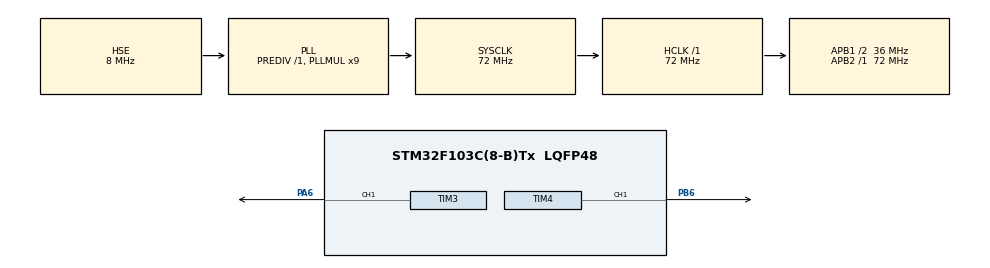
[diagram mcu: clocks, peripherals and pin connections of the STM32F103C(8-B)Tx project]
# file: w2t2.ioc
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Mcu.Family=STM32F1
Mcu.Name=STM32F103C(8-B)Tx
Mcu.Package=LQFP48
NVIC.PriorityGroup=NVIC_PRIORITYGROUP_4
NVIC.TIM2_IRQn=true\:0\:0\:false\:false\:true\:true\:true\:true
PA13.Mode=Serial_Wire
PA13.Signal=SYS_JTMS-SWDIO
PA14.Mode=Serial_Wire
PA14.Signal=SYS_JTCK-SWCLK
PA6.Signal=S_TIM3_CH1
PB6.Signal=S_TIM4_CH1
PD0-OSC_IN.Mode=HSE-External-Oscillator
PD0-OSC_IN.Signal=RCC_OSC_IN
PD1-OSC_OUT.Mode=HSE-External-Oscillator
PD1-OSC_OUT.Signal=RCC_OSC_OUT
ProjectManager.HeapSize=0x200
ProjectManager.StackSize=0x400
ProjectManager.TargetToolchain=MDK-ARM V5.32
RCC.AHBFreq_Value=72000000
RCC.APB1CLKDivider=RCC_HCLK_DIV2
RCC.APB1Freq_Value=36000000
RCC.APB1TimFreq_Value=72000000
RCC.APB2Freq_Value=72000000
RCC.APB2TimFreq_Value=72000000
RCC.HCLKFreq_Value=72000000
RCC.PLLMUL=RCC_PLL_MUL9
RCC.PLLSourceVirtual=RCC_PLLSOURCE_HSE
RCC.SYSCLKFreq_VALUE=72000000
RCC.SYSCLKSource=RCC_SYSCLKSOURCE_PLLCLK
RCC.USBFreq_Value=72000000
SH.S_TIM3_CH1.0=TIM3_CH1,PWM Generation1 CH1
SH.S_TIM4_CH1.0=TIM4_CH1,PWM Generation1 CH1
TIM2.Period=9999
TIM2.Prescaler=71
TIM3.Channel-PWM\ Generation1\ CH1=TIM_CHANNEL_1
TIM3.Period=999
TIM3.Prescaler=71
TIM4.Channel-PWM\ Generation1\ CH1=TIM_CHANNEL_1
TIM4.Period=19999
TIM4.Prescaler=71
VP_TIM2_VS_ClockSourceINT.Mode=Internal
VP_TIM3_VS_ClockSourceINT.Mode=Internal
VP_TIM4_VS_ClockSourceINT.Mode=Internal
board=custom

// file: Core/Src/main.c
/* USER CODE BEGIN Header */
/**
  ******************************************************************************
  * @file           : main.c
  * @brief          : Main program body
  ******************************************************************************
  * @attention
  *
  * Copyright (c) 2026 STMicroelectronics.
  * All rights reserved.
  *
  * This software is licensed under terms that can be found in the LICENSE file
  * in the root directory of this software component.
  * If no LICENSE file comes with this software, it is provided AS-IS.
  *
  ******************************************************************************
  */
/* USER CODE END Header */
#include "main.h"

TIM_HandleTypeDef htim2;
TIM_HandleTypeDef htim3;
TIM_HandleTypeDef htim4;

/* USER CODE BEGIN PV */
uint8_t light_is_up = 1;  //1代表灯正在从暗变亮,0反之.
volatile uint32_t light_ccr_val = 0;  //灯初始从0的全暗开始  加上volatile代表这个变量经常变防止编译器恶搞

uint8_t servo_is_clockwise = 1;  //代表舵机初始的时候顺时针转
volatile uint32_t servo_angle = 0;  //代表舵机旋转的角度,范围在0到180 转到0或者180就反过来

/* USER CODE END PV */

void SystemClock_Config(void);
static void MX_GPIO_Init(void);
static void MX_TIM3_Init(void);
static void MX_TIM2_Init(void);
static void MX_TIM4_Init(void);
/* USER CODE BEGIN PFP */
uint32_t angle_to_ccr(uint32_t angle);

/* USER CODE END PFP */

int main(void)
{

  /* MCU Configuration--------------------------------------------------------*/

  /* Reset of all peripherals, Initializes the Flash interface and the Systick. */
  HAL_Init();

  /* Configure the system clock */
  SystemClock_Config();

  /* Initialize all configured peripherals */
  MX_GPIO_Init();
  MX_TIM3_Init();
  MX_TIM2_Init();
  MX_TIM4_Init();
  /* USER CODE BEGIN 2 */

HAL_TIM_PWM_Start(&htim3, TIM_CHANNEL_1);
HAL_TIM_Base_Start_IT(&htim2);
HAL_TIM_PWM_Start(&htim4, TIM_CHANNEL_1);

  /* USER CODE END 2 */

  /* Infinite loop */
  /* USER CODE BEGIN WHILE */
  while (1)////////////////////////////////////////////////////////////////////////////////////////////
  {
    __HAL_TIM_SET_COMPARE(&htim3, TIM_CHANNEL_1, light_ccr_val);
    __HAL_TIM_SET_COMPARE(&htim4, TIM_CHANNEL_1, angle_to_ccr(servo_angle));
    /* USER CODE END WHILE */

  }
}

void SystemClock_Config(void)
{
  RCC_OscInitTypeDef RCC_OscInitStruct = {0};
  RCC_ClkInitTypeDef RCC_ClkInitStruct = {0};

  /** Initializes the RCC Oscillators according to the specified parameters
  * in the RCC_OscInitTypeDef structure.
  */
  RCC_OscInitStruct.OscillatorType = RCC_OSCILLATORTYPE_HSE;
  RCC_OscInitStruct.HSEState = RCC_HSE_ON;
  RCC_OscInitStruct.HSEPredivValue = RCC_HSE_PREDIV_DIV1;
  RCC_OscInitStruct.HSIState = RCC_HSI_ON;
  RCC_OscInitStruct.PLL.PLLState = RCC_PLL_ON;
  RCC_OscInitStruct.PLL.PLLSource = RCC_PLLSOURCE_HSE;
  RCC_OscInitStruct.PLL.PLLMUL = RCC_PLL_MUL9;
  if (HAL_RCC_OscConfig(&RCC_OscInitStruct) != HAL_OK)
  {
    Error_Handler();
  }

  /** Initializes the CPU, AHB and APB buses clocks
  */
  RCC_ClkInitStruct.ClockType = RCC_CLOCKTYPE_HCLK|RCC_CLOCKTYPE_SYSCLK
                              |RCC_CLOCKTYPE_PCLK1|RCC_CLOCKTYPE_PCLK2;
  RCC_ClkInitStruct.SYSCLKSource = RCC_SYSCLKSOURCE_PLLCLK;
  RCC_ClkInitStruct.AHBCLKDivider = RCC_SYSCLK_DIV1;
  RCC_ClkInitStruct.APB1CLKDivider = RCC_HCLK_DIV2;
  RCC_ClkInitStruct.APB2CLKDivider = RCC_HCLK_DIV1;

  if (HAL_RCC_ClockConfig(&RCC_ClkInitStruct, FLASH_LATENCY_2) != HAL_OK)
  {
    Error_Handler();
  }
}

static void MX_TIM2_Init(void)
{

  TIM_ClockConfigTypeDef sClockSourceConfig = {0};
  TIM_MasterConfigTypeDef sMasterConfig = {0};

  htim2.Instance = TIM2;
  htim2.Init.Prescaler = 71;
  htim2.Init.CounterMode = TIM_COUNTERMODE_UP;
  htim2.Init.Period = 9999;
  htim2.Init.ClockDivision = TIM_CLOCKDIVISION_DIV1;
  htim2.Init.AutoReloadPreload = TIM_AUTORELOAD_PRELOAD_DISABLE;
  if (HAL_TIM_Base_Init(&htim2) != HAL_OK)
  {
    Error_Handler();
  }
  sClockSourceConfig.ClockSource = TIM_CLOCKSOURCE_INTERNAL;
  if (HAL_TIM_ConfigClockSource(&htim2, &sClockSourceConfig) != HAL_OK)
  {
    Error_Handler();
  }
  sMasterConfig.MasterOutputTrigger = TIM_TRGO_RESET;
  sMasterConfig.MasterSlaveMode = TIM_MASTERSLAVEMODE_DISABLE;
  if (HAL_TIMEx_MasterConfigSynchronization(&htim2, &sMasterConfig) != HAL_OK)
  {
    Error_Handler();
  }

}

static void MX_TIM3_Init(void)
{

  TIM_ClockConfigTypeDef sClockSourceConfig = {0};
  TIM_MasterConfigTypeDef sMasterConfig = {0};
  TIM_OC_InitTypeDef sConfigOC = {0};

  htim3.Instance = TIM3;
  htim3.Init.Prescaler = 71;
  htim3.Init.CounterMode = TIM_COUNTERMODE_UP;
  htim3.Init.Period = 999;
  htim3.Init.ClockDivision = TIM_CLOCKDIVISION_DIV1;
  htim3.Init.AutoReloadPreload = TIM_AUTORELOAD_PRELOAD_DISABLE;
  if (HAL_TIM_Base_Init(&htim3) != HAL_OK)
  {
    Error_Handler();
  }
  sClockSourceConfig.ClockSource = TIM_CLOCKSOURCE_INTERNAL;
  if (HAL_TIM_ConfigClockSource(&htim3, &sClockSourceConfig) != HAL_OK)
  {
    Error_Handler();
  }
  if (HAL_TIM_PWM_Init(&htim3) != HAL_OK)
  {
    Error_Handler();
  }
  sMasterConfig.MasterOutputTrigger = TIM_TRGO_RESET;
  sMasterConfig.MasterSlaveMode = TIM_MASTERSLAVEMODE_DISABLE;
  if (HAL_TIMEx_MasterConfigSynchronization(&htim3, &sMasterConfig) != HAL_OK)
  {
    Error_Handler();
  }
  sConfigOC.OCMode = TIM_OCMODE_PWM1;
  sConfigOC.Pulse = 0;
  sConfigOC.OCPolarity = TIM_OCPOLARITY_HIGH;
  sConfigOC.OCFastMode = TIM_OCFAST_DISABLE;
  if (HAL_TIM_PWM_ConfigChannel(&htim3, &sConfigOC, TIM_CHANNEL_1) != HAL_OK)
  {
    Error_Handler();
  }
  HAL_TIM_MspPostInit(&htim3);

}

static void MX_TIM4_Init(void)
{

  TIM_ClockConfigTypeDef sClockSourceConfig = {0};
  TIM_MasterConfigTypeDef sMasterConfig = {0};
  TIM_OC_InitTypeDef sConfigOC = {0};

  htim4.Instance = TIM4;
  htim4.Init.Prescaler = 71;
  htim4.Init.CounterMode = TIM_COUNTERMODE_UP;
  htim4.Init.Period = 19999;
  htim4.Init.ClockDivision = TIM_CLOCKDIVISION_DIV1;
  htim4.Init.AutoReloadPreload = TIM_AUTORELOAD_PRELOAD_DISABLE;
  if (HAL_TIM_Base_Init(&htim4) != HAL_OK)
  {
    Error_Handler();
  }
  sClockSourceConfig.ClockSource = TIM_CLOCKSOURCE_INTERNAL;
  if (HAL_TIM_ConfigClockSource(&htim4, &sClockSourceConfig) != HAL_OK)
  {
    Error_Handler();
  }
  if (HAL_TIM_PWM_Init(&htim4) != HAL_OK)
  {
    Error_Handler();
  }
  sMasterConfig.MasterOutputTrigger = TIM_TRGO_RESET;
  sMasterConfig.MasterSlaveMode = TIM_MASTERSLAVEMODE_DISABLE;
  if (HAL_TIMEx_MasterConfigSynchronization(&htim4, &sMasterConfig) != HAL_OK)
  {
    Error_Handler();
  }
  sConfigOC.OCMode = TIM_OCMODE_PWM1;
  sConfigOC.Pulse = 0;
  sConfigOC.OCPolarity = TIM_OCPOLARITY_HIGH;
  sConfigOC.OCFastMode = TIM_OCFAST_DISABLE;
  if (HAL_TIM_PWM_ConfigChannel(&htim4, &sConfigOC, TIM_CHANNEL_1) != HAL_OK)
  {
    Error_Handler();
  }
  HAL_TIM_MspPostInit(&htim4);

}

static void MX_GPIO_Init(void)
{

  /* GPIO Ports Clock Enable */
  __HAL_RCC_GPIOD_CLK_ENABLE();
  __HAL_RCC_GPIOA_CLK_ENABLE();
  __HAL_RCC_GPIOB_CLK_ENABLE();

}

/* USER CODE BEGIN 4 */

void HAL_TIM_PeriodElapsedCallback(TIM_HandleTypeDef *htim)
{
  if(htim->Instance == TIM2)
  {
    if (light_ccr_val == 0) {
      light_is_up = 1;
    } else if (light_ccr_val == 1000) {
      light_is_up = 0;
    }
    if (light_is_up == 0) {
      light_ccr_val -=10 ;
    } else {
      light_ccr_val += 10;
    }

////////////////////////////////以上是呼吸灯的逻辑

    if (servo_angle == 0) {
      servo_is_clockwise = 1;
    }else if (servo_angle == 180) {
      servo_is_clockwise = 0;
    }

    if (servo_is_clockwise == 1) {
      servo_angle += 1;
    }else {
    servo_angle -= 1;
    }

  }
}

uint32_t angle_to_ccr(uint32_t angle)
{
  return  (100*angle/9.0f)+500;
}

/* USER CODE END 4 */

void Error_Handler(void)
{
  __disable_irq();
  while (1)
  {
  }
}
